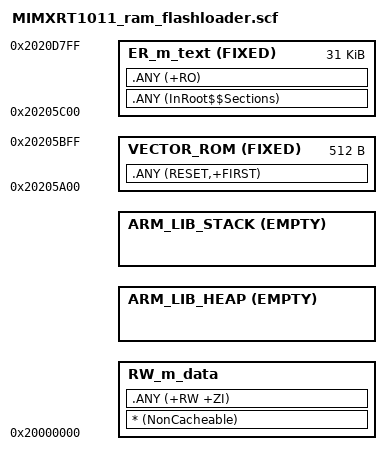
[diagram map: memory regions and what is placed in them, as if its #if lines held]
#! armcc -E
/*
** ###################################################################
**     Processors:          MIMXRT1011CAE4A
**                          MIMXRT1011DAE5A
**
**     Compiler:            Keil ARM C/C++ Compiler
**     Reference manual:    IMXRT1010RM Rev.A, 03/2019
**     Version:             rev. 0.1, 2019-02-14
**     Build:               b190723
**
**     Abstract:
**         Linker file for the Keil ARM C/C++ Compiler
**
**     Copyright 2016 Freescale Semiconductor, Inc.
**     Copyright 2016-2019 NXP
**     All rights reserved.
**
**     SPDX-License-Identifier: BSD-3-Clause
**
**     http:                 www.nxp.com
**     mail:                 support@nxp.com
**
** ###################################################################
*/

#define m_interrupts_start             0x20205a00
#define m_interrupts_size              0x00000200

#define m_text_start                   0x20205c00
#define m_text_size                    0x00007c00

#define m_data_start                   0x20000000
#define m_data_size                    0x00005800

/* Sizes */
#if (defined(__stack_size__))
  #define Stack_Size                   __stack_size__
#else
  #define Stack_Size                   0x1000
#endif

#if (defined(__heap_size__))
  #define Heap_Size                    __heap_size__
#else
  #define Heap_Size                    0x0
#endif

LR_m_text m_interrupts_start m_interrupts_size+m_text_size {   ; load region size_region
  VECTOR_ROM m_interrupts_start FIXED m_interrupts_size { ; load address = execution address
    .ANY (RESET,+FIRST)
  }
  ER_m_text m_text_start FIXED m_text_size { ; load address = execution address
    .ANY (InRoot$$Sections)
    .ANY (+RO)
  }
  RW_m_data m_data_start m_data_size-Stack_Size-Heap_Size { ; RW data
    * (NonCacheable)
    .ANY (+RW +ZI)
  }
  ARM_LIB_HEAP +0 EMPTY Heap_Size {    ; Heap region growing up
  }
  ARM_LIB_STACK m_data_start+m_data_size EMPTY -Stack_Size { ; Stack region growing down
  }
}
